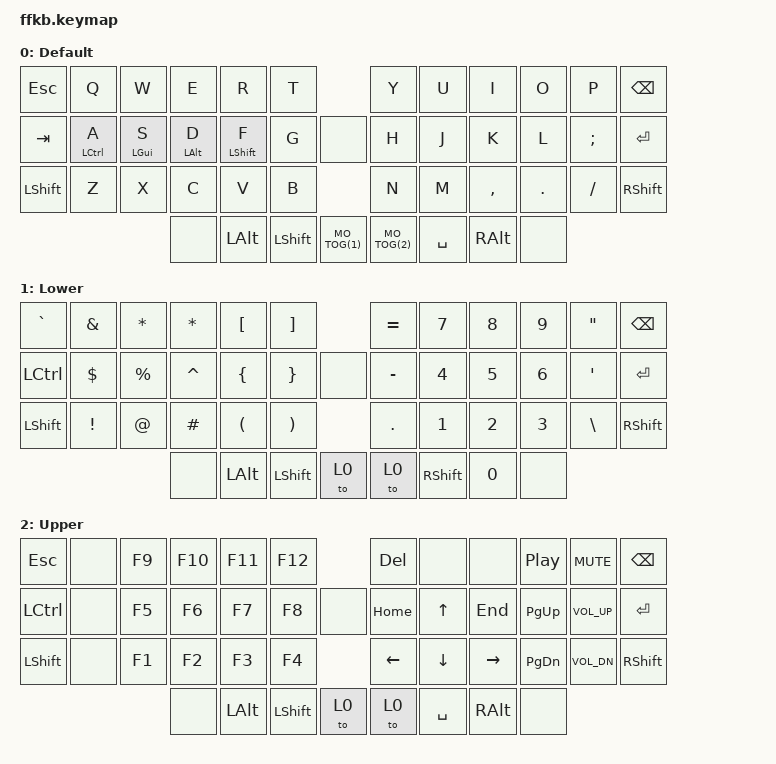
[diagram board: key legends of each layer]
#include <behaviors.dtsi>
#include <dt-bindings/zmk/keys.h>
#include <dt-bindings/zmk/bt.h>
#include <dt-bindings/zmk/outputs.h>


#define DEFAULT 0
#define LOWER   1
#define UPPER   2

#define MO_TOG(layer) &mo_tog layer layer   // Macro to apply momentary-layer-on-hold/toggle-layer-on-tap to a specific layer

/ {
    behaviors {
        hm: homerow_mods {
            compatible = "zmk,behavior-hold-tap";
            label = "HOMEROW_MODS";
            #binding-cells = <2>;
            tapping-term-ms = <200>;
            quick_tap_ms = <0>;
            flavor = "balanced";
            bindings = <&kp>, <&kp>;
        };
        hs: homerow_shift {
            compatible = "zmk,behavior-hold-tap";
            label = "HOMEROW_MODS";
            #binding-cells = <2>;
            tapping-term-ms = <175>;
            quick_tap_ms = <0>;
            flavor = "balanced";
            bindings = <&kp>, <&kp>;
        };
        hst: homerow_stickey {
            compatible = "zmk,behavior-hold-tap";
            label = "HOMEROW_TOGGLE";
            #binding-cells = <2>;
            tapping-term-ms = <175>;
            quick_tap_ms = <0>;
            flavor = "balanced";
            bindings = <&sk>, <&kp>;
        };
        mo_tog: behavior_mo_tog {
            compatible = "zmk,behavior-hold-tap";
            label = "mo_tog";
            #binding-cells = <2>;
            flavor = "hold-preferred";
            tapping-term-ms = <200>;
            bindings = <&mo>, <&tog>;
        };
    };

    keymap {
        compatible = "zmk,keymap";

        default_layer {
            label = "Default";
// --------------------------------------------------------------------------------------------------------------------------------------------------------------------
// |   ESC   |    Q    |    W    |    E    |    R    |    T    |                    |    Y    |    U    |    I    |    O    |    P    |   BSPC  |
// |   TAB   |    A    |    S    |    D    |    F    |    G    |                    |    H    |    J    |    K    |    L    |    ;    | RETURN  |
// |  SHIFT  |    Z    |    X    |    C    |    V    |    B    |                    |    N    |    M    |    ,    |    .    |    /    |  SHIFT  |
//                                         |   ALT   |  LSHIFT |  LOWER | |  UPPER  |  SPACE  |  RALT   |
            bindings = <
    &kp ESC    &kp Q       &kp W       &kp E       &kp R         &kp T                               &kp Y     &kp U     &kp I     &kp O     &kp P    &kp BSPC
    &kp TAB    &hst LCTRL A &hst LGUI S &hm LALT D  &hs LSHIFT F  &kp G              &none            &kp H     &kp J     &kp K     &kp L     &kp SEMI &kp RETURN
    &kp LSHIFT &kp Z       &kp X       &kp C       &kp V         &kp B                               &kp N     &kp M     &kp COMMA &kp DOT   &kp FSLH &kp RSHIFT
                                       &none       &kp LALT      &kp LSHIFT  MO_TOG(1)   MO_TOG(2)   &kp SPACE &kp RALT  &none
            >;
        };
        
        lower_layer {
            label = "Lower";
// --------------------------------------------------------------------------------------------------------------------------------------------------------------------
// |   `     |    &    |    *    |    *    |    [    |     ]    |                    |    =    |    7    |    8    |    9    |    "    |    -    |   BSPC  |
// |   CTRL  |    $    |    %    |    ^    |    {    |     }    |                    |    -    |    4    |    5    |    6    |    '    | RETURN  |
// |  SHIFT  |    !    |    @    |    #    |    (    |     )    |                    |    .    |    1    |    2    |    3    |    \    |  SHIFT  |
//                                         |   ALT   |  LSHIFT  |    -   | |    -    |  RSHIFT |    0    |
            bindings = < 
    &kp GRAVE    &kp AMPS   &kp ASTRK    &kp ASTRK  &kp LEFT_BRACKET  &kp RIGHT_BRACKET                     &kp EQUAL  &kp N7   &kp N8  &kp N9   &kp DQT        &kp BSPC
    &kp LCTRL    &kp DOLLAR &kp PERCENT  &kp CARET  &kp LEFT_BRACE    &kp RIGHT_BRACE         &none         &kp MINUS  &kp N4   &kp N5  &kp N6   &kp SQT        &kp RETURN
    &kp LSHIFT   &kp EXCL   &kp AT       &kp HASH   &kp LPAR          &kp RPAR                              &kp DOT    &kp N1   &kp N2  &kp N3   &kp BACKSLASH  &kp RSHIFT
                                         &none      &kp LALT          &kp LSHIFT         &to 0     &to 0    &kp RSHIFT &kp N0   &none
            >;
        };

        upper_layer {
            label = "Upper";
// --------------------------------------------------------------------------------------------------------------------------------------------------------------------
// |   ESC   |   -   |    F9    |    F10   |    F11    |    F12   |                 |  DELETE |    -    |    -   | Play/Pause |    mute   |   BSPC  |
// |   CTRL  |   -   |    F5    |    F6    |    F7     |    F8    |                 |   HOME  |   ⬆    |   END   |  PAGE_UP  |   vol up   | RETURN  |
// |  SHIFT  |   -   |    F1    |    F2    |    F3     |    F4    |                 |    ⬅   |    ⬇    |   ⮕    | PAGE_DOWN |  vol down  |  SHIFT  |
//                                          |    ALT   |   SHIFT  |  TD |    |  TD  |  SPACE  |   ALT   |
            bindings = <
    &kp ESC      &none   &kp F9    &kp F10   &kp F11   &kp F12                      &kp DELETE       &none          &none            &kp C_PP      &kp K_MUTE   &kp BSPC
    &kp LCTRL    &none   &kp F5    &kp F6    &kp F7    &kp F8           &none       &kp HOME         &kp UP_ARROW   &kp END          &kp PAGE_UP   &kp C_VOL_UP &kp RETURN
    &kp LSHIFT   &none   &kp F1    &kp F2    &kp F3    &kp F4                       &kp LEFT_ARROW   &kp DOWN_ARROW &kp RIGHT_ARROW  &kp PAGE_DOWN &kp C_VOL_DN &kp RSHIFT
                                   &none     &kp LALT  &kp LSHIFT   &to 0   &to 0   &kp SPACE        &kp RALT       &none
            >;
        };
    };
};
